# R7FA4W1AD register map
Vendor: Renesas; Series: RA4; File version: 1.0
CPU: CM4 r0p1, little endian, MPU, FPU, VTOR, 4 interrupt priority bits
Registers are 8-bit, read-write, reset 0x0 unless marked. A register's access mark holds for its fields unless they carry their own. Offsets are from the block's base; [hi:lo] are bit positions; 'fields as' and 'values as' point back to an identical list.

## FCACHE — Flash Cache
Base 0x4001C000
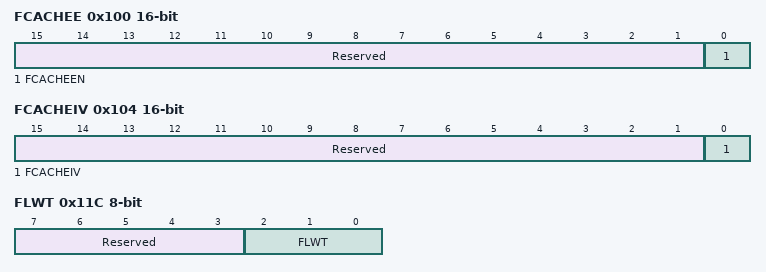
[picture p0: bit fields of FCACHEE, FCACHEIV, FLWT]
0x100 FCACHEE 16-bit — Flash Cache Enable Register
  [15:1] Reserved — These bits are read as 000000000000000. The write value should be 000000000000000.
  [0] FCACHEEN — FCACHE Enable
    0=FCACHE is disabled; 1=FCACHE is enabled
0x104 FCACHEIV 16-bit — Flash Cache Invalidate Register
  [15:1] Reserved — These bits are read as 000000000000000. The write value should be 000000000000000.
  [0] FCACHEIV write-1-sets read-modifies — FCACHE Invalidation
    0=(Read)not in progress / (Write) no effect; 1=(Read)in progress /(Write) Starting Cache Invalidation
0x11C FLWT — Flash Wait Cycle Register
  [7:3] Reserved — These bits are read as 00000. The write value should be 00000.
  [2:0] FLWT — These bits represent the ratio of the CPU clock period to the Flash memory access time.
    0=zero wait; other=others (Setting prohibited)

## DMA — DMAC Module Activation
Base 0x40005200
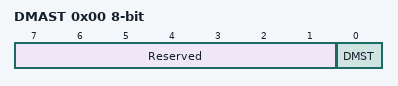
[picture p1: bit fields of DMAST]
0x00 DMAST — DMAC Module Activation Register
  [7:1] Reserved — These bits are read as 0000000. The write value should be 0000000.
  [0] DMST — DMAC Operation Enable
    0=Disabled; 1=Enabled

## DBG — Debug Function
Base 0x4001B000
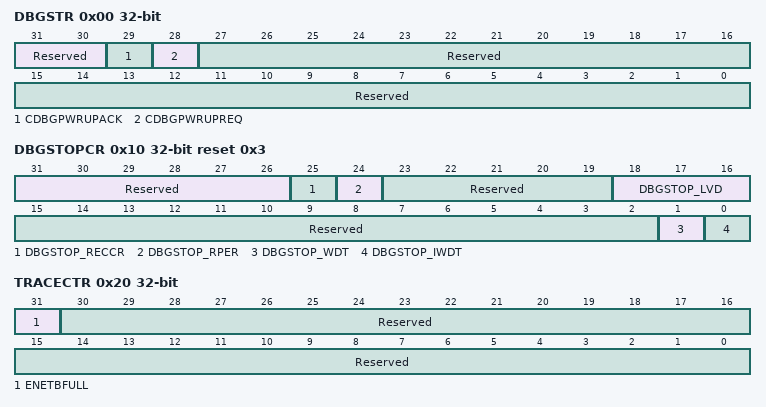
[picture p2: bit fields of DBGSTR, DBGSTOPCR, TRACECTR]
0x00 DBGSTR 32-bit ro — Debug Status Register
  [31:30] Reserved — These bits are read as 00.
  [29] CDBGPWRUPACK — Debug power-up acknowledge
    0=Debug power-up request is not acknowledged; 1=Debug power-up request is acknowledged
  [28] CDBGPWRUPREQ — Debug power-up request
    0=OCD is not requesting debug power-up; 1=OCD is requesting debug power-up
  [27:0] Reserved — These bits are read as 0000000000000000000000000000.
0x10 DBGSTOPCR 32-bit reset 0x3 — Debug Stop Control Register
  [31:26] Reserved — These bits are read as 000000. The write value should be 000000.
  [25] DBGSTOP_RECCR — Mask bit for RAM ECC error reset/interrupt
    0=Enable RAM ECC error reset/interrupt; 1=Mask RAM ECC error reset/interrupt
  [24] DBGSTOP_RPER — Mask bit for RAM parity error reset/interrupt
    0=Enable RAM parity error reset/interrupt; 1=Mask RAM parity error reset/interrupt
  [23:19] Reserved — These bits are read as 00000. The write value should be 00000.
  [18:16] DBGSTOP_LVD — b18: Mask bit for LVD2 reset/interrupt (0:enable / 1:Mask)b17: Mask bit for LVD1 reset/interrupt (0:enable / 1:Mask)b16: Mask bit for LVD0 reset (0:enable / 1:Mask)
  [15:2] Reserved — These bits are read as 00000000000000. The write value should be 00000000000000.
  [1] DBGSTOP_WDT — Mask bit for WDT reset/interrupt
    0=Mask WDT reset/interrupt; 1=Enable WDT reset
  [0] DBGSTOP_IWDT — Mask bit for IWDT reset/interrupt
    0=Mask IWDT reset/interrupt; 1=Enable IWDT reset
0x20 TRACECTR 32-bit — Trace Control Register
  [31] ENETBFULL — Enable bit for halt request by ETB full
    0=ETB full does not cause CPU halt; 1=ETB full cause CPU halt
  [30:0] Reserved — These bits are read as 0000000000000000000000000000000. The write value should be 0000000000000000000000000000000.

## SRAM — SRAM Control
Base 0x40002000
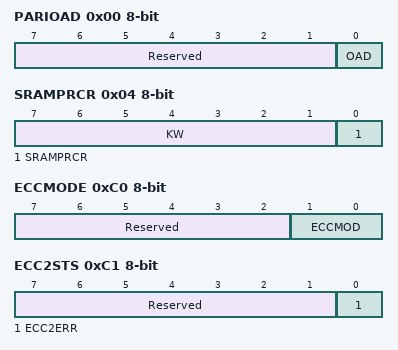
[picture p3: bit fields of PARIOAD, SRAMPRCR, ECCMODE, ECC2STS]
0x00 PARIOAD — SRAM Parity Error Operation After Detection Register
  [7:1] Reserved — These bits are read as 0000000. The write value should be 0000000.
  [0] OAD — Operation after Detection
    1=Reset; 0=Non maskable interrupt
0x04 SRAMPRCR — SRAM Protection Register
  [7:1] KW wo — Write Key Code
    120=Writing to the RAMPRCR bit is valid, when the KEY bits are written 1111000b; other=others (Writing to the RAMPRCR bit is invalid.)
  [0] SRAMPRCR — Register Write Control
    0=Disable writes to protected registers; 1=Enable writes to protected registers
0xC0 ECCMODE — ECC Operating Mode Control Register
  [7:2] Reserved — These bits are read as 000000. The write value should be 000000.
  [1:0] ECCMOD — ECC Operating Mode Select
    0=Disable ECC function; 1=Setting prohibited; 2=Enable ECC function without error checking; 3=Enable ECC function with error checking
0xC1 ECC2STS — ECC 2-Bit Error Status Register
  [7:1] Reserved — These bits are read as 0000000. The write value should be 0000000.
  [0] ECC2ERR write-0-clears read-modifies — ECC 2-Bit Error Status
    0=No 2-bit ECC error occurred; 1=2-bit ECC error occurred
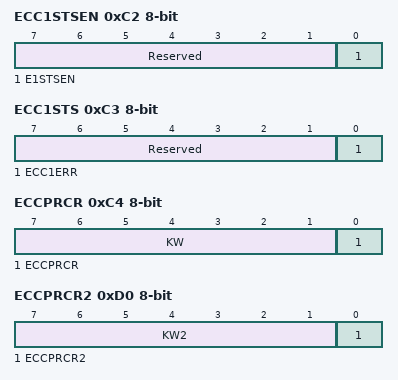
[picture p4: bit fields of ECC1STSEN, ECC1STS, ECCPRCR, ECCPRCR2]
0xC2 ECC1STSEN — ECC 1-Bit Error Information Update Enable Register
  [7:1] Reserved — These bits are read as 0000000. The write value should be 0000000.
  [0] E1STSEN — ECC 1-Bit Error Information Update Enable
    0=Disables updating of the 1-bit ECC error information; 1=Enables updating of the 1-bit ECC error information
0xC3 ECC1STS — ECC 1-Bit Error Status Register
  [7:1] Reserved — These bits are read as 0000000. The write value should be 0000000.
  [0] ECC1ERR write-0-clears read-modifies — ECC 1-Bit Error Status
    0=No 1-bit ECC error occurred; 1=1-bit ECC error occurred
0xC4 ECCPRCR — ECC Protection Register
  [7:1] KW wo — Write Key Code
    120=Writing to the ECCRAMPRCR bit is valid, when the KEY bits are written 1111000b; other=others (Writing to the ECCRAMPRCR bit is invalid.)
  [0] ECCPRCR — Register Write Control
    0=Disable writes to the protected registers; 1=Enable writes to the protected registers
0xD0 ECCPRCR2 — ECC Protection Register 2
  [7:1] KW2 wo — Write Key Code
    120=These bits enable or disable writes to the ECCPRCR2 bit; other=others (Writing to the ECCRAMPRCR2 bit is invalid.)
  [0] ECCPRCR2 — Register Write Control
    values as ECCPRCR.ECCPRCR
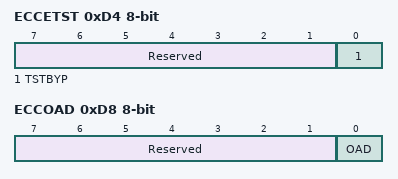
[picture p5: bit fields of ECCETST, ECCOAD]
0xD4 ECCETST — ECC Test Control Register
  [7:1] Reserved — These bits are read as 0000000. The write value should be 0000000.
  [0] TSTBYP — ECC Bypass Select
    0=ECC bypass disabled; 1=ECC bypass enabled
0xD8 ECCOAD — SRAM ECC Error Operation After Detection Register
  [7:1] Reserved — These bits are read as 0000000. The write value should be 0000000.
  [0] OAD — Operation after Detection
    0=Non-maskable interrupt; 1=Reset
